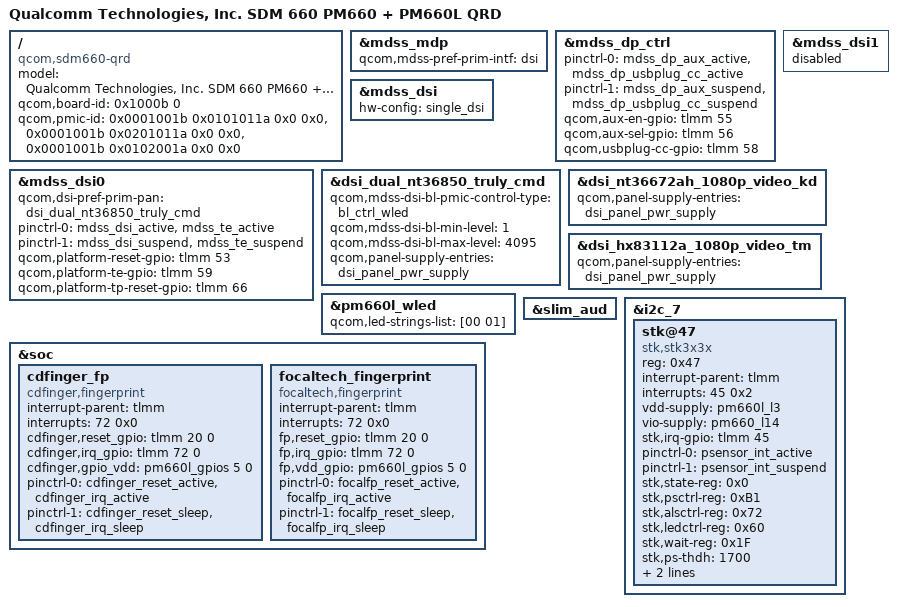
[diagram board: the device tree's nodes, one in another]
/* Copyright (c) 2016-2017, The Linux Foundation. All rights reserved.
 *
 * This program is free software; you can redistribute it and/or modify
 * it under the terms of the GNU General Public License version 2 and
 * only version 2 as published by the Free Software Foundation.
 *
 * This program is distributed in the hope that it will be useful,
 * but WITHOUT ANY WARRANTY; without even the implied warranty of
 * MERCHANTABILITY or FITNESS FOR A PARTICULAR PURPOSE.  See the
 * GNU General Public License for more details.
 */


/dts-v1/;

#include "sdm660.dtsi"
#include "sdm660-qrd.dtsi"
#include "sdm660-internal-codec.dtsi"

#include "X01BD/overlay.dtsi"
#include "X01BD/sdm660-qrd-overlay.dtsi"
#include "X01BD/sdm660-internal-codec-overlay.dtsi"

/ {
	model = "Qualcomm Technologies, Inc. SDM 660 PM660 + PM660L QRD";
	compatible = "qcom,sdm660-qrd", "qcom,sdm660", "qcom,qrd";
	qcom,board-id = <0x1000b 0>;
	qcom,pmic-id = <0x0001001b 0x0101011a 0x0 0x0>,
			<0x0001001b 0x0201011a 0x0 0x0>,
			<0x0001001b 0x0102001a 0x0 0x0>;
};

&mdss_mdp {
	qcom,mdss-pref-prim-intf = "dsi";
};

&mdss_dp_ctrl {
	pinctrl-names = "mdss_dp_active", "mdss_dp_sleep";
	pinctrl-0 = <&mdss_dp_aux_active &mdss_dp_usbplug_cc_active>;
	pinctrl-1 = <&mdss_dp_aux_suspend &mdss_dp_usbplug_cc_suspend>;
	qcom,aux-en-gpio = <&tlmm 55 0>;
	qcom,aux-sel-gpio = <&tlmm 56 0>;
	qcom,usbplug-cc-gpio = <&tlmm 58 0>;
};

&mdss_dsi {
	hw-config = "single_dsi";
};

&mdss_dsi0 {
	qcom,dsi-pref-prim-pan = <&dsi_dual_nt36850_truly_cmd>;
	pinctrl-names = "mdss_default", "mdss_sleep";
	pinctrl-0 = <&mdss_dsi_active &mdss_te_active>;
	pinctrl-1 = <&mdss_dsi_suspend &mdss_te_suspend>;
	qcom,platform-reset-gpio = <&tlmm 53 0>;
	qcom,platform-te-gpio = <&tlmm 59 0>;
	qcom,platform-tp-reset-gpio = <&tlmm 66 0>;
};

&mdss_dsi1 {
	status = "disabled";
};

&dsi_dual_nt36850_truly_cmd {
	qcom,mdss-dsi-bl-pmic-control-type = "bl_ctrl_wled";
	qcom,mdss-dsi-bl-min-level = <1>;
	qcom,mdss-dsi-bl-max-level = <4095>;
	qcom,panel-supply-entries = <&dsi_panel_pwr_supply>;
};

&dsi_nt36672ah_1080p_video_kd {
	  qcom,panel-supply-entries = <&dsi_panel_pwr_supply>;
};

&dsi_hx83112a_1080p_video_tm {
	  qcom,panel-supply-entries = <&dsi_panel_pwr_supply>;
};

&pm660l_wled {
	qcom,led-strings-list = [00 01];
};

&soc {
	cdfinger_fp {
		compatible = "cdfinger,fingerprint";
		interrupt-parent = <&tlmm>;
		interrupts = <72 0x0>;
		cdfinger,reset_gpio = <&tlmm 20 0>;
		cdfinger,irq_gpio = <&tlmm 72 0>;
		cdfinger,gpio_vdd = <&pm660l_gpios 5 0>;

		pinctrl-names = "cdfinger_active",
				"cdfinger_sleep";
		pinctrl-0 = <&cdfinger_reset_active &cdfinger_irq_active>;
		pinctrl-1 = <&cdfinger_reset_sleep &cdfinger_irq_sleep>;
	};

	focaltech_fingerprint {
		compatible = "focaltech,fingerprint";
		interrupt-parent = <&tlmm>;
		interrupts = <72 0x0>;
		fp,reset_gpio   = <&tlmm 20 0>;
		fp,irq_gpio        = <&tlmm 72 0>;
		fp,vdd_gpio        = <&pm660l_gpios 5 0>;

		pinctrl-names = "focalfp_active",
				"focalfp_sleep";
		pinctrl-0 = <&focalfp_reset_active &focalfp_irq_active>;
		pinctrl-1 = <&focalfp_reset_sleep &focalfp_irq_sleep>;
	};
};

&slim_aud {
	/delete-node/wcd934x_cdc;
};

&soc {
	/delete-node/sound-tavil;
};

&i2c_7 { /* for P/L Sensor */
	status = "okay";

	stk@47 {
		compatible = "stk,stk3x3x";
		reg = <0x47>;
		interrupt-parent = <&tlmm>;
		interrupts = <45 0x2>;
		vdd-supply = <&pm660l_l3>;
		vio-supply = <&pm660_l14>;
		stk,irq-gpio = <&tlmm 45 0x02>;

		pinctrl-names = "psensor_active", "psensor_suspend";
		pinctrl-0 = <&psensor_int_active>;
		pinctrl-1 = <&psensor_int_suspend>;

		stk,state-reg = <0x0>;
		stk,psctrl-reg = <0xB1>;
		stk,alsctrl-reg = <0x72>;
		stk,ledctrl-reg = <0x60>;
		stk,wait-reg = <0x1F>;
		stk,ps-thdh = <1700>;
		stk,ps-thdl = <1500>;
		stk,transmittance = <1100>;
	};
};
